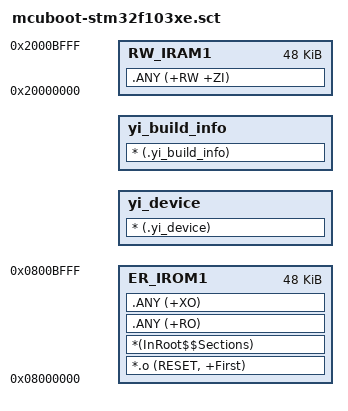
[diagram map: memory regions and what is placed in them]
; STM32F103xE MCUboot region: 48 KiB at the beginning of internal flash.
LR_IROM1 0x08000000 0x0000C000 {
  ER_IROM1 0x08000000 0x0000C000 {
    *.o (RESET, +First)
    *(InRoot$$Sections)
    .ANY (+RO)
    .ANY (+XO)
  }

  yi_device +0 ALIGN 4 {
    * (.yi_device)
  }

  yi_build_info +0 ALIGN 4 {
    * (.yi_build_info)
  }

  RW_IRAM1 0x20000000 0x0000C000 {
    .ANY (+RW +ZI)
  }
}
